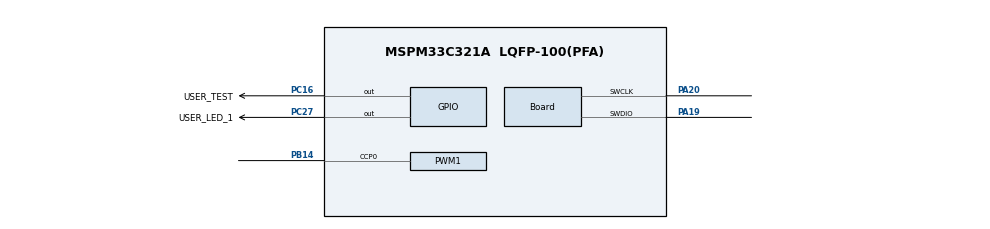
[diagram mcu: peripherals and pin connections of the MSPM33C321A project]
//@cliArgs --device "MSPM33C321A" --package "LQFP-100(PFA)" --part "Default"
//@v2CliArgs --device "MSPM33C321A" --package "LQFP-100(PFA)"
// @cliArgs --board /ti/boards/LP_MSPM33C321A --rtos nortos

/**
 * Import the modules used in this configuration.
 */
const GPIO          = scripting.addModule("/ti/driverlib/GPIO", {}, false);
const GPIO1         = GPIO.addInstance();
const PWM           = scripting.addModule("/ti/driverlib/PWM", {}, false);
const PWM1          = PWM.addInstance();
const SYSCTL        = scripting.addModule("/ti/driverlib/SYSCTL");
const ProjectConfig = scripting.addModule("/ti/project_config/ProjectConfig");

/**
 * Write custom configuration values to the imported modules.
 */
GPIO1.$name                                 = "GPIO_LEDS";
GPIO1.associatedPins.create(2);
GPIO1.associatedPins[0].$name               = "USER_LED_1";
GPIO1.associatedPins[0].launchPadShortcut   = "LED2GreenEn";
GPIO1.associatedPins[0].pin.$assign         = "PC27";
GPIO1.associatedPins[1].$name               = "USER_TEST";
GPIO1.associatedPins[1].assignedPortSegment = "Upper";
GPIO1.associatedPins[1].assignedPin         = "16";
GPIO1.associatedPins[1].assignedPort        = "PORTC";
GPIO1.associatedPins[1].pin.$assign         = "PC16";

const Board                       = scripting.addModule("/ti/driverlib/Board", {}, false);
Board.peripheral.$assign          = "DEBUGSS";
Board.peripheral.swclkPin.$assign = "PA20";
Board.peripheral.swdioPin.$assign = "PA19";

PWM1.$name                          = "PWM_0";
PWM1.dbRiseDelayTimerCount          = 50;
PWM1.dbFallDelayTimerCount          = 25;
PWM1.ccIndex                        = [0];
PWM1.clockPrescale                  = 32;
PWM1.timerCount                     = 8191;
PWM1.enableShadowLoad               = true;
PWM1.interrupts                     = ["CC0_DN_EVENT"];
PWM1.PWM_CHANNEL_0.$name            = "ti_driverlib_pwm_PWMTimerCC0";
PWM1.PWM_CHANNEL_0.ccValue          = 799;
PWM1.PWM_CHANNEL_0.shadowUpdateMode = "ZERO_EVT";
PWM1.ccp0PinConfig.$name            = "ti_driverlib_gpio_GPIOPinGeneric0";
PWM1.peripheral.$assign             = "TIMA0_0";
PWM1.peripheral.ccp0Pin.$assign     = "PB14";

SYSCTL.forceDefaultClkConfig = true;
SYSCTL.peripheral.$assign    = "SYSCTL";

ProjectConfig.genLinker          = true;
ProjectConfig.genStartup         = true;
ProjectConfig.genOpts            = true;
ProjectConfig.genLibs            = true;
ProjectConfig.migrationCondition = true;
